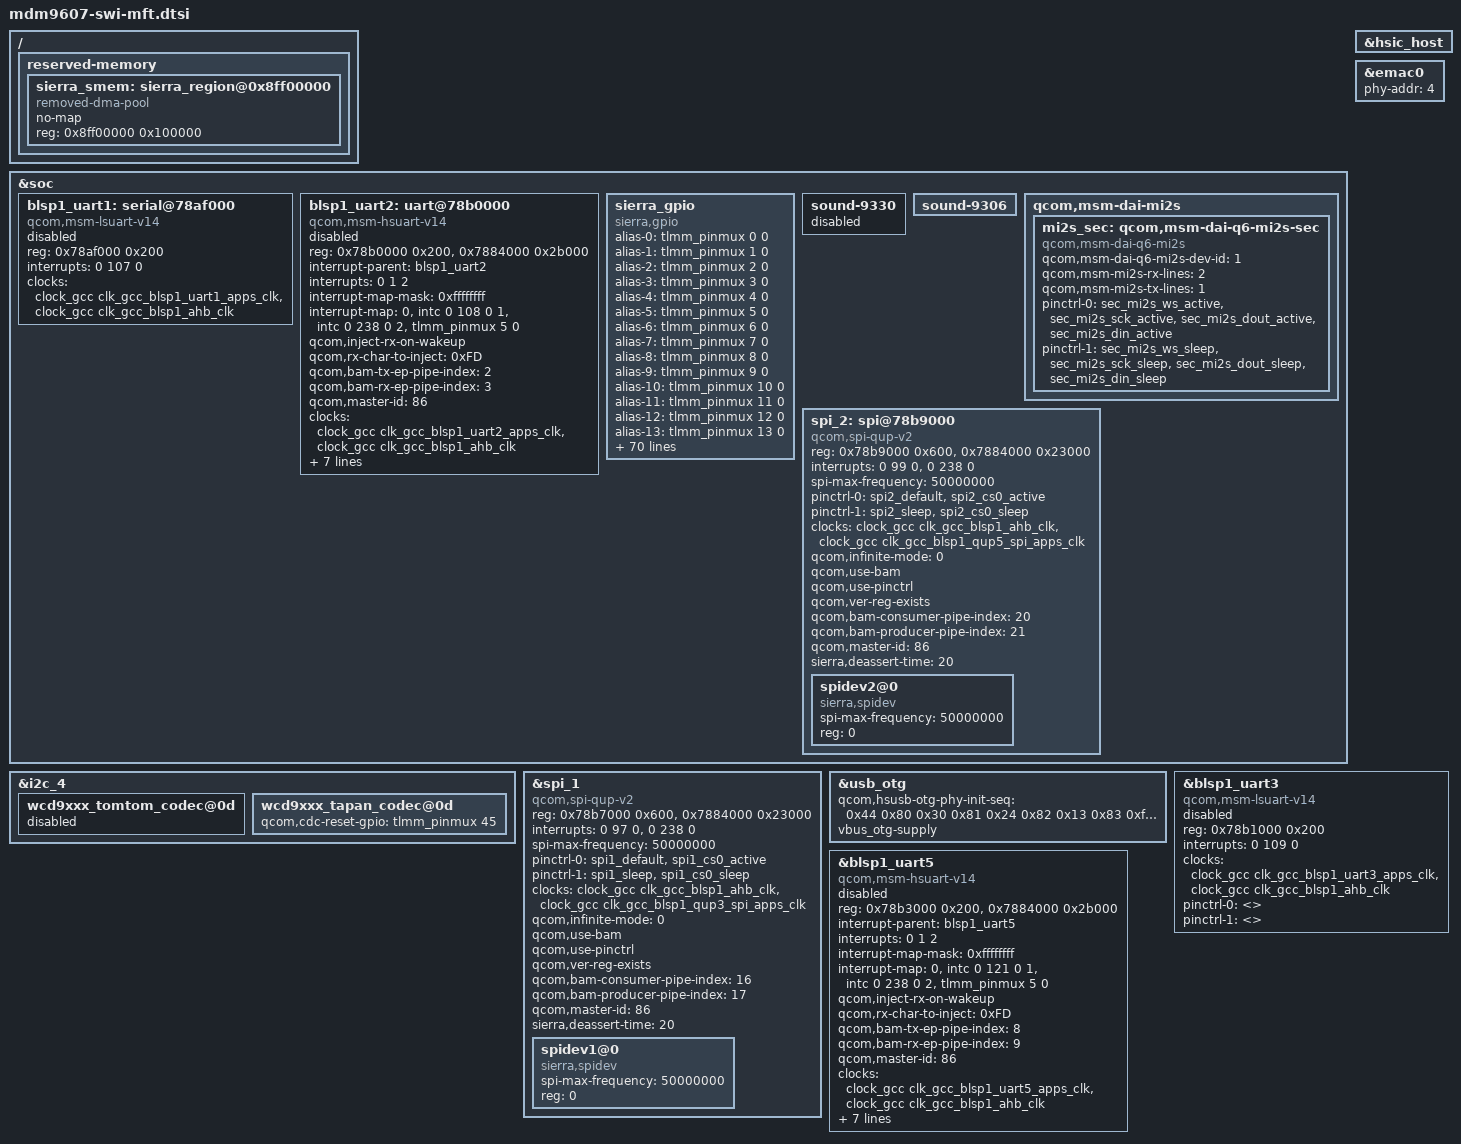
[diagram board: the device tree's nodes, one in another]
/*
 * Copyright (c) 2015-2016, The Linux Foundation. All rights reserved.
 *
 * This program is free software; you can redistribute it and/or modify
 * it under the terms of the GNU General Public License version 2 and
 * only version 2 as published by the Free Software Foundation.
 *
 * This program is distributed in the hope that it will be useful,
 * but WITHOUT ANY WARRANTY; without even the implied warranty of
 * MERCHANTABILITY or FITNESS FOR A PARTICULAR PURPOSE.  See the
 * GNU General Public License for more details.
 */
#include "mdm9607.dtsi"

/ {
	reserved-memory {
		#address-cells = <1>;
		#size-cells = <1>;
		ranges;

		sierra_smem: sierra_region@0x8ff00000 {
			compatible = "removed-dma-pool";
			no-map;
			reg = <0x8ff00000 0x100000>;
		};
	};
};

&soc {
	#address-cells = <1>;
	#size-cells = <1>;
	ranges;

	blsp1_uart1: serial@78af000 { /* BLSP1 UART1 */
		compatible = "qcom,msm-lsuart-v14";
		reg = <0x78af000 0x200>;
		interrupts = <0 107 0>;

		clocks = <&clock_gcc clk_gcc_blsp1_uart1_apps_clk>,
			 <&clock_gcc clk_gcc_blsp1_ahb_clk>;
		clock-names = "core_clk", "iface_clk";
		status = "disabled";
	};

	blsp1_uart2: uart@78b0000 {
		compatible = "qcom,msm-hsuart-v14";
		reg = <0x78b0000 0x200>,
			<0x7884000 0x2b000>;
		reg-names = "core_mem", "bam_mem";
		interrupt-names = "core_irq", "bam_irq", "wakeup_irq";
		#address-cells = <0>;
		interrupt-parent = <&blsp1_uart2>;
		interrupts = <0 1 2>;
		#interrupt-cells = <1>;
		interrupt-map-mask = <0xffffffff>;
		interrupt-map = <0 &intc 0 108 0
				1 &intc 0 238 0
				2 &tlmm_pinmux 5 0>;

		qcom,inject-rx-on-wakeup;
		qcom,rx-char-to-inject = <0xFD>;
		qcom,bam-tx-ep-pipe-index = <2>;
		qcom,bam-rx-ep-pipe-index = <3>;
		qcom,master-id = <86>;
		clock-names = "core_clk", "iface_clk";
		clocks = <&clock_gcc clk_gcc_blsp1_uart2_apps_clk>,
			<&clock_gcc clk_gcc_blsp1_ahb_clk>;
		pinctrl-names = "sleep", "default";
		pinctrl-0 = <&blsp1_uart2_sleep>;
		pinctrl-1 = <&blsp1_uart2_active>;
		qcom,msm-bus,name = "blsp1_uart2";
		qcom,msm-bus,num-cases = <2>;
		qcom,msm-bus,num-paths = <1>;
		qcom,msm-bus,vectors-KBps =
					<86 512 0 0>,
					<86 512 500 800>;
		status = "disabled";
	};

	sierra_gpio {
		compatible = "sierra,gpio";
		alias-0 = <&tlmm_pinmux 0 0>;
		alias-1 = <&tlmm_pinmux 1 0>;
		alias-2 = <&tlmm_pinmux 2 0>;
		alias-3 = <&tlmm_pinmux 3 0>;
		alias-4 = <&tlmm_pinmux 4 0>;
		alias-5 = <&tlmm_pinmux 5 0>;
		alias-6 = <&tlmm_pinmux 6 0>;
		alias-7 = <&tlmm_pinmux 7 0>;
		alias-8 = <&tlmm_pinmux 8 0>;
		alias-9 = <&tlmm_pinmux 9 0>;
		alias-10 = <&tlmm_pinmux 10 0>;
		alias-11 = <&tlmm_pinmux 11 0>;
		alias-12 = <&tlmm_pinmux 12 0>;
		alias-13 = <&tlmm_pinmux 13 0>;
		alias-14 = <&tlmm_pinmux 14 0>;
		alias-15 = <&tlmm_pinmux 15 0>;
		alias-16 = <&tlmm_pinmux 16 0>;
		alias-17 = <&tlmm_pinmux 17 0>;
		alias-18 = <&tlmm_pinmux 18 0>;
		alias-19 = <&tlmm_pinmux 19 0>;
		alias-20 = <&tlmm_pinmux 20 0>;
		alias-21 = <&tlmm_pinmux 21 0>;
		alias-22 = <&tlmm_pinmux 22 0>;
		alias-23 = <&tlmm_pinmux 23 0>;
		alias-24 = <&tlmm_pinmux 24 0>;
		alias-25 = <&tlmm_pinmux 25 0>;
		alias-26 = <&tlmm_pinmux 26 0>;
		alias-27 = <&tlmm_pinmux 27 0>;
		alias-28 = <&tlmm_pinmux 28 0>;
		alias-29 = <&tlmm_pinmux 29 0>;
		alias-30 = <&tlmm_pinmux 30 0>;
		alias-31 = <&tlmm_pinmux 31 0>;
		alias-32 = <&tlmm_pinmux 32 0>;
		alias-33 = <&tlmm_pinmux 33 0>;
		alias-34 = <&tlmm_pinmux 34 0>;
		alias-35 = <&tlmm_pinmux 35 0>;
		alias-36 = <&tlmm_pinmux 36 0>;
		alias-37 = <&tlmm_pinmux 37 0>;
		alias-38 = <&tlmm_pinmux 38 0>;
		alias-39 = <&tlmm_pinmux 39 0>;
		alias-40 = <&tlmm_pinmux 40 0>;
		alias-41 = <&tlmm_pinmux 41 0>;
		alias-42 = <&tlmm_pinmux 42 0>;
		alias-43 = <&tlmm_pinmux 43 0>;
		alias-44 = <&tlmm_pinmux 44 0>;
		alias-45 = <&tlmm_pinmux 45 0>;
		alias-46 = <&tlmm_pinmux 46 0>;
		alias-47 = <&tlmm_pinmux 47 0>;
		alias-48 = <&tlmm_pinmux 48 0>;
		alias-49 = <&tlmm_pinmux 49 0>;
		alias-50 = <&tlmm_pinmux 50 0>;
		alias-51 = <&tlmm_pinmux 51 0>;
		alias-52 = <&tlmm_pinmux 52 0>;
		alias-53 = <&tlmm_pinmux 53 0>;
		alias-54 = <&tlmm_pinmux 54 0>;
		alias-55 = <&tlmm_pinmux 55 0>;
		alias-56 = <&tlmm_pinmux 56 0>;
		alias-57 = <&tlmm_pinmux 57 0>;
		alias-58 = <&tlmm_pinmux 58 0>;
		alias-59 = <&tlmm_pinmux 59 0>;
		alias-60 = <&tlmm_pinmux 60 0>;
		alias-61 = <&tlmm_pinmux 61 0>;
		alias-62 = <&tlmm_pinmux 62 0>;
		alias-63 = <&tlmm_pinmux 63 0>;
		alias-64 = <&tlmm_pinmux 64 0>;
		alias-65 = <&tlmm_pinmux 65 0>;
		alias-66 = <&tlmm_pinmux 66 0>;
		alias-67 = <&tlmm_pinmux 67 0>;
		alias-68 = <&tlmm_pinmux 68 0>;
		alias-69 = <&tlmm_pinmux 69 0>;
		alias-70 = <&tlmm_pinmux 70 0>;
		alias-71 = <&tlmm_pinmux 71 0>;
		alias-72 = <&tlmm_pinmux 72 0>;
		alias-73 = <&tlmm_pinmux 73 0>;
		alias-74 = <&tlmm_pinmux 74 0>;
		alias-75 = <&tlmm_pinmux 75 0>;
		alias-76 = <&tlmm_pinmux 76 0>;
		alias-77 = <&tlmm_pinmux 77 0>;
		alias-78 = <&tlmm_pinmux 78 0>;
		alias-79 = <&tlmm_pinmux 79 0>;
		alias-80 = <&pm8019_gpios 3 (-1)>;
		alias-81 = <&pm8019_gpios 4 (-1)>;
		alias-82 = <&pm8019_gpios 6 (-1)>;
		alias-83 = <&pm8019_gpios 5 (-1)>;
	};

	sound-9330 {
		status = "disabled";
		};
	sound-9306 {
		status = "ok";
		};

	qcom,msm-dai-mi2s {
		mi2s_sec: qcom,msm-dai-q6-mi2s-sec {
			compatible = "qcom,msm-dai-q6-mi2s";
			qcom,msm-dai-q6-mi2s-dev-id = <1>;
			qcom,msm-mi2s-rx-lines = <2>;
			qcom,msm-mi2s-tx-lines = <1>;

			pinctrl-names = "default", "idle";
			pinctrl-0 = <&sec_mi2s_ws_active
					&sec_mi2s_sck_active
					&sec_mi2s_dout_active
					&sec_mi2s_din_active>;
			pinctrl-1 = <&sec_mi2s_ws_sleep
					&sec_mi2s_sck_sleep
					&sec_mi2s_dout_sleep
					&sec_mi2s_din_sleep>;

		};
	};

	spi_2: spi@78b9000 { /* BLSP1 QUP4 */
		compatible = "qcom,spi-qup-v2";
		#address-cells = <1>;
		#size-cells = <0>;
		reg-names = "spi_physical", "spi_bam_physical";
		reg = <0x78b9000 0x600>,
		      <0x7884000 0x23000>;
		interrupt-names = "spi_irq", "spi_bam_irq";
		interrupts = <0 99 0>, <0 238 0>;
		spi-max-frequency = <50000000>;
		pinctrl-names = "spi_default", "spi_sleep";
		pinctrl-0 = <&spi2_default &spi2_cs0_active>;
		pinctrl-1 = <&spi2_sleep &spi2_cs0_sleep>;
		clocks = <&clock_gcc clk_gcc_blsp1_ahb_clk>,
			 <&clock_gcc clk_gcc_blsp1_qup5_spi_apps_clk>;
		clock-names = "iface_clk", "core_clk";
		qcom,infinite-mode = <0>;
		qcom,use-bam;
		qcom,use-pinctrl;
		qcom,ver-reg-exists;
		qcom,bam-consumer-pipe-index = <20>;
		qcom,bam-producer-pipe-index = <21>;
		qcom,master-id = <86>;
		sierra,deassert-time = <20>;
		spidev2@0 {
			compatible = "sierra,spidev";
			spi-max-frequency = <50000000>;
			reg = <0>;
		};
	};
};

&i2c_4 { /* BLSP1 QUP4 */
        wcd9xxx_tomtom_codec@0d{
			status = "disabled";
			};
	wcd9xxx_tapan_codec@0d{
		status = "ok";
		qcom,cdc-reset-gpio = <&tlmm_pinmux 45 0>;
	};
};

&spi_1 { /* BLSP1 QUP2 */
	compatible = "qcom,spi-qup-v2";
	#address-cells = <1>;
	#size-cells = <0>;
	reg-names = "spi_physical", "spi_bam_physical";
	reg = <0x78b7000 0x600>,
		  <0x7884000 0x23000>;
	interrupt-names = "spi_irq", "spi_bam_irq";
	interrupts = <0 97 0>, <0 238 0>;
	spi-max-frequency = <50000000>;
	pinctrl-names = "spi_default", "spi_sleep";
	pinctrl-0 = <&spi1_default &spi1_cs0_active>;
	pinctrl-1 = <&spi1_sleep &spi1_cs0_sleep>;
	clocks = <&clock_gcc clk_gcc_blsp1_ahb_clk>,
		 <&clock_gcc clk_gcc_blsp1_qup3_spi_apps_clk>;
	clock-names = "iface_clk", "core_clk";
	qcom,infinite-mode = <0>;
	qcom,use-bam;
	qcom,use-pinctrl;
	qcom,ver-reg-exists;
	qcom,bam-consumer-pipe-index = <16>;
	qcom,bam-producer-pipe-index = <17>;
	qcom,master-id = <86>;
	sierra,deassert-time = <20>;
	spidev1@0 {
		compatible = "sierra,spidev";
		spi-max-frequency = <50000000>;
		reg = <0>;
	};
};

&usb_otg {
	qcom,hsusb-otg-phy-init-seq =
		<0x44 0x80 0x30 0x81 0x24 0x82 0x13 0x83 0xffffffff>;

	vbus_otg-supply;
};

&hsic_host {
	status = "ok";
};

&emac0 {
	/* sierra hardware(RXD0 is 0, RXD1 is 0, LED_ACT is 1): so the address should be 4*/
	phy-addr = <4>;
};

&blsp1_uart3 {
	compatible = "qcom,msm-lsuart-v14";
	reg = <0x78b1000 0x200>;
	interrupts = <0 109 0>;
	clocks = <&clock_gcc clk_gcc_blsp1_uart3_apps_clk>,
		 <&clock_gcc clk_gcc_blsp1_ahb_clk>;
	clock-names = "core_clk", "iface_clk";
	pinctrl-0 = <>;
	pinctrl-1 = <>;
	status = "disabled";
};

&blsp1_uart5 {
	compatible = "qcom,msm-hsuart-v14";
	reg = <0x78b3000 0x200>,
		<0x7884000 0x2b000>;
	reg-names = "core_mem", "bam_mem";
	interrupt-names = "core_irq", "bam_irq", "wakeup_irq";
	#address-cells = <0>;
	interrupt-parent = <&blsp1_uart5>;
	interrupts = <0 1 2>;
	#interrupt-cells = <1>;
	interrupt-map-mask = <0xffffffff>;
	interrupt-map = <0 &intc 0 121 0
			1 &intc 0 238 0
			2 &tlmm_pinmux 5 0>;

	qcom,inject-rx-on-wakeup;
	qcom,rx-char-to-inject = <0xFD>;
	qcom,bam-tx-ep-pipe-index = <8>;
	qcom,bam-rx-ep-pipe-index = <9>;
	qcom,master-id = <86>;
	clock-names = "core_clk", "iface_clk";
	clocks = <&clock_gcc clk_gcc_blsp1_uart5_apps_clk>,
		<&clock_gcc clk_gcc_blsp1_ahb_clk>;
	pinctrl-names = "sleep", "default";
	pinctrl-0 = <&blsp1_uart5_sleep>;
	pinctrl-1 = <&blsp1_uart5_active>;
	qcom,msm-bus,name = "blsp1_uart5";
	qcom,msm-bus,num-cases = <2>;
	qcom,msm-bus,num-paths = <1>;
	qcom,msm-bus,vectors-KBps =
				<86 512 0 0>,
				<86 512 500 800>;
	status = "disabled";
};
